# psoc4000t register map
Vendor: Cypress Semiconductor; Series: PSoC4000T; File version: 1.0
CPU: CM0PLUS r0p1, little endian, no MPU, no FPU, VTOR, 2 interrupt priority bits
Registers are 32-bit, read-write, reset 0x0 unless marked. A register's access mark holds for its fields unless they carry their own. Offsets are from the block's base; [hi:lo] are bit positions; lines under a group give offsets from that group; {n}, {i} and the like mark numbered series; 'fields as' and 'values as' point back to an identical list; <NAME> marks a mode.

## MSCLP0 (part 3 of 3) — Low Power MultiSense Converter
Base 0x40290000
0x2000 SNS group — Sensor Configuration Structure (clk_imo_msc domain)
  {0x0+4j} SENSOR_DATA[{j}] (j=0..1023) — Sensor Configuration Storage
    [31:0] DATA — Local IP storage to support per-sensor configuration and results for AS-MS/LP-AoS mode. The per sensor registers all have the prefix SNS_* in the SNS_STRUCTLP register tab. Firmware Rule: SENSOR_DATA represents design time parameter SRAM_SIZE (0,1,2,4) kB of storage that is usable for autonomous sensor configuration data and result data. It is accessed via 32-bit word indices. Firmware must program the following registers in a manner to allow for SENSOR_DATA to be used for both purposes (configuration and result). Sensor configuration: FRAME_CFG_START_ADDR is set by software to indicate to hardware where the first sensor scan configuration structure exists in SENSOR_DATA to start processing a frame (typically set to 0x0). The size of each configuration structure depends on what software sets for CFG_OFFSET (see description of this register for more details). Autonomous scanning will execute sequential structures (size defined by CFG_OFFSET) until it encounters a structure with SNS_CTL.LAST set. This defines the end of the frame. Sensor results: FRAME_RES_START_ADDR is set by software to define the base address (in 32-bit words) of the result FIFO (where the frame raw counts are stored). The depth of the FIFO is inferred by the setting for FRAME_RES_START_ADDR and the size of the memory integrated by the IP (SRAM_SIZE parameter). For example if SRAM_SIZE = 1kB, there are 256x 32-bit entries in the SRAM (0->255). If FRAME_RES_START_ADDR is set to 224, then the FIFO depth = 255-224+1 = 32. The result data is directly accessible by firmware via SENSOR_DATA (with an understanding of FRAME_RES_START_ADDR to know which index in SENSOR_DATA to access). The result FIFO can also be accessed as a FIFO via RESULT_FIFO_RD, which always points to the head of the FIFO (as tracked by hardware) and a read to this register pops the top result off this FIFO. See description of RESULT_FIFO_RD for details. Note that depending on the size of the SRAM macro integrated with the IP, and the amount of sensors being scanned (and amount of autonomous configuration required) - it is possible to have multiple sets of frame configuration and/or have the result FIFO sized to store multiple frames of data.
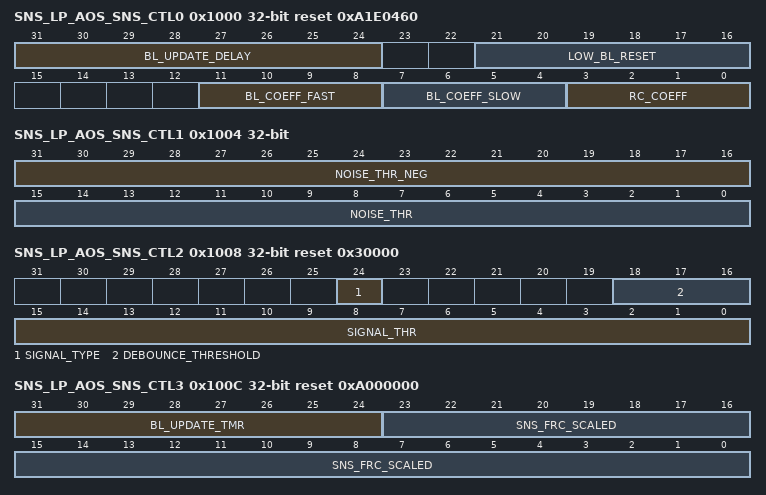
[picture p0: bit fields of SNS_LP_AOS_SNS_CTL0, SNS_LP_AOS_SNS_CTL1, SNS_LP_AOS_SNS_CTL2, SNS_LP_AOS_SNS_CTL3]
  0x1000 SNS_LP_AOS_SNS_CTL0 reset 0xA1E0460 — LP-AoS Sensor Control 0
    [31:24] BL_UPDATE_DELAY — Specifies the value from which BL_UPDATE_TMR is decremented from on consecutive scans where the baseline update IIR produces a zero. Used to enable a bucket filter at a programmable tuning rate.
    [21:16] LOW_BL_RESET — Specifies the value from which BL_RESET_TMR is decremented from on consecutive scans where diff as per SIGNAL_TYPE is below NOISE_THR and -diff is above NOISE_THR_NEG.
    [11:8] BL_COEFF_FAST — Baseline update IIR coefficient when baseline update state is fast. Firmware Rule: Must be > 0. Typical range [4,8].
      1=MIN (N/A)
    [7:4] BL_COEFF_SLOW — Baseline update IIR coefficient when baseline update state is slow. Firmware Rule: Must be > 0. Typical range [4,8].
      1=MIN (N/A)
    [3:0] RC_COEFF — Raw count filter coefficient. Firmware Rule: Legal range [0,8].
      8=MAX (N/A)
  0x1004 SNS_LP_AOS_SNS_CTL1 — LP-AoS Sensor Control 1
    [31:16] NOISE_THR_NEG — Sensor baseline negative noise threshold.
    [15:0] NOISE_THR — Sensor baseline noise threshold.
  0x1008 SNS_LP_AOS_SNS_CTL2 reset 0x30000 — LP-AoS Sensor Control 2
    [24] SIGNAL_TYPE — Setting that specifies whether the raw counts increase or decrease when the sensor is excited by an event (e.g. when a finger approaches a sensor - if self-cap sensing is used, the raw counts increase, but if mutual-cap sensing is used the raw counts decrease). '0': Positive - raw counts increase on event so for baselining diff = raw_count - baseline '1': Negative - raw counts decrease on event so for baselining diff = raw_count - baseline
      0=POSITIVE (N/A); 1=NEGATIVE (N/A)
    [18:16] DEBOUNCE_THRESHOLD — Global threshold for successive SIGNAL_THR exceeds to warrant a full system wakeup.
    [15:0] SIGNAL_THR — Per sensor threshold for |baseline - rawCount| to warrant a signal detect.
  0x100C SNS_LP_AOS_SNS_CTL3 reset 0xA000000 — LP-AoS Sensor Control 3
    [31:24] BL_UPDATE_TMR — Sensor baseline update timer. Decremented from BL_UPDATE_DELAY on consecutive scans where the baseline update IIR produces a zero. Used to enable a bucket filter.
    [23:0] SNS_FRC_SCALED — Sensor raw count filter IIR state (filtered raw count scaled).
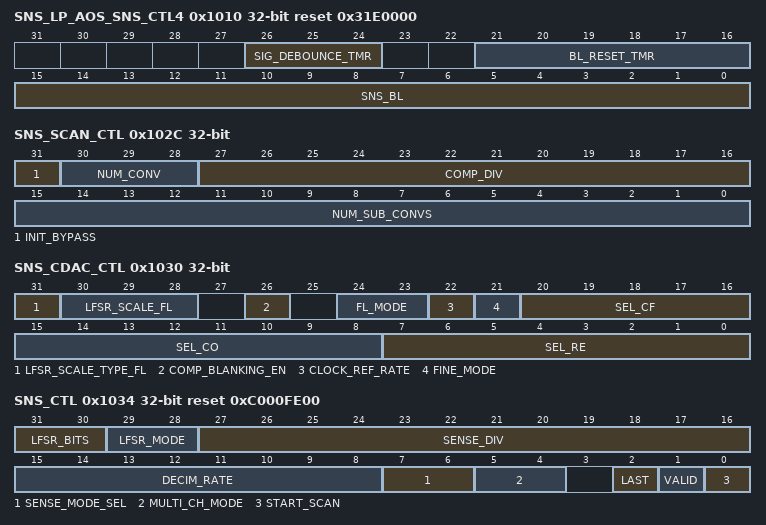
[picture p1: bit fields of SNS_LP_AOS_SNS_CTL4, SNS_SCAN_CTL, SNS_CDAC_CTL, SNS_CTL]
  0x1010 SNS_LP_AOS_SNS_CTL4 reset 0x31E0000 — LP-AoS Sensor Control 4
    [26:24] SIG_DEBOUNCE_TMR — Sensor signal detect debounce timer. Decremented from DEBOUNCE_THRESHOLD on consecutive scans with a signal detection.
    [21:16] BL_RESET_TMR — Sensor low baseline reset timer. Decremented from LOW_BL_RESET tuning parameter on consecutive scans where diff as per SIGNAL_TYPE is below NOISE_THR and -diff is above NOISE_THR_NEG.
    [15:0] SNS_BL — Sensor baseline value.
  0x1014 SNS_SW_SEL_CSW_HI_MASK2 — CapSense Sensor Switch Function Select High Mask 2
    [31:0] FUNC_MASK — {SNS_SW_SEL_CSW_HI_MASK2.FUNC_MASK[x], SNS_SW_SEL_CSW_HI_MASK1.FUNC_MASK[x], SNS_SW_SEL_CSW_HI_MASK0.FUNC_MASK[x]} used to select appropriate SW_SEL_CSW_FUNC[x] when CSW_FUNC_MODE[x] = 1.
  0x1018 SNS_SW_SEL_CSW_HI_MASK1 — CapSense Sensor Switch Function Select High Mask 1
    fields as SNS.SNS_SW_SEL_CSW_HI_MASK2
  0x101C SNS_SW_SEL_CSW_HI_MASK0 — CapSense Sensor Switch Function Select High Mask 0
    fields as SNS.SNS_SW_SEL_CSW_HI_MASK2
  0x1020 SNS_SW_SEL_CSW_LO_MASK2 — CapSense Sensor Switch Function Select Low Mask 2
    [31:0] FUNC_MASK — {SNS_SW_SEL_CSW_LO_MASK2.FUNC_MASK[x], SNS_SW_SEL_CSW_LO_MASK1.FUNC_MASK[x], SNS_SW_SEL_CSW_LO_MASK0.FUNC_MASK[x]} used to select appropriate SW_SEL_CSW_FUNC[x] when CSW_FUNC_MODE[x] = 1.
  0x1024 SNS_SW_SEL_CSW_LO_MASK1 — CapSense Sensor Switch Function Select Low Mask 1
    fields as SNS.SNS_SW_SEL_CSW_LO_MASK2
  0x1028 SNS_SW_SEL_CSW_LO_MASK0 — CapSense Sensor Switch Function Select Low Mask 0
    fields as SNS.SNS_SW_SEL_CSW_LO_MASK2
  0x102C SNS_SCAN_CTL — Sensor Scan Control
    [31] INIT_BYPASS — Coarse initialisation bypass control. Applies to CMOD_SEL selected Cmod.
      0=DISABLED (N/A); 1=ENABLED (N/A)
    [30:28] NUM_CONV — Number of conversions (minus 1) per scanned sample. This is required for chopping (chop polarity is updated per conversion).
      0=ONE (N/A); 1=TWO (N/A); 3=FOUR (N/A); 7=EIGHT (N/A)
    [27:16] COMP_DIV — The ratio (minus 1) of clk_comp::clk_mod. Notes for tuning: Fs = Fmod / Kref Fcomp = Kcomp * Fs MSCv3 MMIO provides: Kref = (SENSE_DIV+1) Fs = Fmod/(SENSE_DIV+1) Fcomp = Fmod / (COMP_DIV+1) Therefore: Kcomp = Fmod/[Fs*(COMP_DIV+1)] Kcomp = (SENSE_DIV+1)/(COMP_DIV+1) Hardware Overriding: Note that clk_comp runs at clk_ref (and associated duty cycle) during PRO_OFFSET, and COMP_DIV does not apply during this time. Firmware Rule: It is expected that Kcomp be programmed as an integer. Anything else is considered a mis-programming.
    [15:0] NUM_SUB_CONVS — Number of sub-conversions (minus 1) in a conversion.
  0x1030 SNS_CDAC_CTL — Sensor CAPDAC Control
    [31] LFSR_SCALE_TYPE_FL — Flatspot/Dither CAPDAC shift direction.
      0=RIGHT (N/A); 1=LEFT (N/A)
    [30:28] LFSR_SCALE_FL — Shift the magnitude portion of the Flatspot/Dither CAPDAC LFSR output code left or right by LSFR_SCALE_FL bits. Direction of shift controlled by LFSR_SCALE_TYPE_FL. Note since the magnitude is 7-bits, the maximum shift is 6-bits. The sign bit does not form part of the shift. Example: 6-bit polynomial (x^6 + x^4 + x^3 + x^2 + 1). lfsr_fl_out[7] = lfsr_fl[5]; // Sign bit always connected in MSB to HardIP. if(LFSR_SCALE_TYPE_FL == LEFT) lfsr_out[6:0] = {2'b00,lfsr[4:0]} << LFSR_SCALE_FL; // Scaled 7-bit magnitude. else lfsr_out[6:0] = {2'b00,lfsr[4:0]} >> LFSR_SCALE_FL; // Scaled 7-bit magnitude.
      6=MAX (N/A)
    [26] COMP_BLANKING_EN — Compensation blanking control. Type of blanking controlled by COMP_BLANKING_MODE. Effect of blanking defined as i) Gate to 0 (not freeze) clk_comp. ii) Open all SW_CO* switches. iii) Open all SW_CF* switches if being used in compensation mode (FINE_MODE = COMPENSATION). Hardware Overriding: General overriding as per general definition above. However the window in which these effects apply depend on the following. When enabled and in Direct Clock and Spread Spectrum mode (LFSR_MODE): 2-Phase: 50 percent Comp: PH0: Enable Comp for (SENSE_DIV+1)/4 (this will be 0.5 of Ph0 phase) PH1: Enable Comp for (SENSE_DIV+1)/4 (this will be 0.5 of Ph1 phase) 25 percent Comp: PH0: Enable Comp for (SENSE_DIV+1)/8 (this will be 0.25 of Ph0 phase) PH1: Enable Comp for (SENSE_DIV+1)/8 (this will be 0.25 of Ph1 phase) 4-Phase: 50 percent Comp: PH1: Enable Comp for (SENSE_DIV+1)/4 (this will be Full of Ph1 phase) PH3: Enable Comp for (SENSE_DIV+1)/4 (this will be Full of Ph3 phase) 25 percent Comp: PH1: Enable Comp for (SENSE_DIV+1)/8 (this will be 0.5 of Ph1 phase) PH3: Enable Comp for (SENSE_DIV+1)/8 (this will be 0.5 of Ph3 phase) Note that in Spread Spectrum mode, if the ph* where compensation is on shrinks from the nominal. So, if we have 50 percent compensation the ph can shrink to be shorter than (SENSE_DIV+1)/4. So for example if ph1 shrinks, this will mean that compensation stays on a bit into ph2. This is OK. When enabled and in PRS mode (LFSR_MODE): 2-Phase PRS: 50 percent Comp: PH0: Enable Comp for (SENSE_DIV+1) (this will be 0.5 of AVG Ph0 and All of MIN Ph0) PH1: Enable Comp for (SENSE_DIV+1) (this will be 0.5 of AVG Ph1 and All of MIN Ph1) 25 percent Comp: PH0: Enable Comp for (SENSE_DIV+1)/2 (this will be 0.25 of AVG Ph0 and 0.5 of Min Ph0) PH1: Enable Comp for (SENSE_DIV+1)/2 (this will be 0.25 of AVG Ph1 and 0.5 of Min Ph1) 4-Phase PRS: 50 percent Comp: PH1: Enable Comp for (SENSE_DIV+1)*2 (this will be All of AVG Ph1 and 2x of Min Ph1 or All of Min Ph1+Min Ph2) PH3: Enable Comp for (SENSE_DIV+1)*2 (this will be All of AVG Ph3 and 2x of Min Ph3 or All of Min Ph3+Min Ph0) 25 percent Comp: PH1: Enable Comp for (SENSE_DIV+1) (this will be 0.5 of AVG Ph1 and All of Min Ph1) PH3: Enable Comp for (SENSE_DIV+1) (this will be 0.5 of AVG Ph3 and All of Min Ph3)
      0=DISABLED (N/A); 1=ENABLED (N/A)
    [24:23] FL_MODE — Dither/Flatspot LFSR enable control. Hardware Overriding: '0': Dither/Flatspot LFSR is disabled. LFSR_SCALE_FL, LFSR_SCALE_TYPE_FL and ACTIVATION_MODE and MSB manipulation logic have no effect. The hard IP is presented with the code 0x00 and SEL_FL programming is ignored. All SW_SEL_CDAC_FL switches are autonomously kept open during PRO_DUMMY, PRO_WAIT, SUB_CONV, EPILOGUE and POST_EPI states. '1': The Dither/Flatspot LFSR is enabled. There is no overriding of SW_SEL_CDAC_FL even if LFSR is at a zero code. '2': Dither/Flatspot LFSR is used as an offset (SEL_FL specified). LFSR_SCALE_FL, LFSR_SCALE_TYPE_FL and ACTIVATION_MODE and MSB manipulation logic have no effect. The hard IP is presented with the code programmed into SEL_FL. If SEL_FL is 0x00 (unlikely programming in this mode), then all SW_SEL_CDAC_FL switches are autonomously kept open for the duration of the PRO_DUMMY, PRO_WAIT, SUB_CONV, EPILOGUE and POST_EPI states.
      0=DISABLED (N/A); 1=DITHER (N/A); 2=OFFSET (N/A)
    [22] CLOCK_REF_RATE — Used to select clk_mod or clk_mod/2 to as clk_ref. This clock is gated depending on the synchronised comparator to generate the gated feedback clock (clk_reffb) to the Reference CAPDAC. '0': Use clk_mod. '1': Use clk_mod/2.
      0=CLK_MOD (N/A); 1=HALF_CLK_MOD (N/A)
    [21] FINE_MODE — Operational mode for Fine CAPDAC
      0=REFERENCE (N/A); 1=COMPENSATION (N/A)
    [20:16] SEL_CF — Select value for Fine CAPDAC size. Hardware Overriding: If SEL_CF = 0 Hardware provides autonomous overriding of all SW_SEL_CDAC_CF to be OPEN for the duration of the PRO_DUMMY, PRO_WAIT, SUB_CONV, EPILOGUE and POST_EPI states. This is true for both FINE_MODE = REFERENCE/COMPENSATION.
    [15:8] SEL_CO — Select value for Compensation CAPDAC size. Hardware Overriding: Note if SEL_CO = 0 and FINE_MODE != COMPENSATION, then clk_comp is gated during PRO_DUMMY, SUB_CONV and EPILOGUE. Additionally: If SEL_CO = 0 Hardware provides autonomous overriding of all SW_SEL_CDAC_CO to be OPEN for the duration of the PRO_DUMMY, PRO_WAIT, SUB_CONV, EPILOGUE and POST_EPI states.
    [7:0] SEL_RE — Select value for Reference CAPDAC size. Hardware Overriding: If SEL_RE = 0 Hardware provides autonomous overriding of all SW_SEL_CDAC_RE to be OPEN for the duration of the PRO_DUMMY, PRO_WAIT, SUB_CONV, EPILOGUE and POST_EPI states.
  0x1034 SNS_CTL reset 0xC000FE00 — Sense Control and Command Register
    [31:30] LFSR_BITS — Selects the number of LSB bits to use from the LSFR to provide the clock dithering variation on the base period (spread spectrum mode). Caveat make sure that SENSE_DIV > the maximum absolute range (e.g. for 4B SENSE_DIV > 8), otherwise results are undefined.
      0=2B (Use 2 bits: range = [-2,1]); 1=3B (Use 3 bits: range = [-4,3]); 2=4B (Use 4 bits: range = [-8,7]); 3=5B (Use 5 bits: range = [-16,15] (default))
    [29:28] LFSR_MODE — Mode for generating the sense clock. '0': Direct Clocking. '1': Spread Spectrum. '2': PRS.
      0=DIRECT_CLOCK (N/A); 1=SPREAD_SPECTRUM (N/A); 2=PRS (N/A)
    [27:16] SENSE_DIV — The length (minus 1) of the sense modulation 'clock' period in clk_mod cycles (frequency = Fs). SENSE_DIV + 1 = sense_ratio = Kref. Note this is the base divider, clock dithering may change the actual period length. Firmware Rule: Firmware is responsible for programming a value in this register to ensure correct operation. When LFSR_MODE = DIRECT_CLOCK, in 2-phase mode sense_ratio needs to be >=4 to allow for digital non-overlap. In 4-phase mode, sense_ratio needs to be >=8. If spread spectrum is enabled (LFSR_MODE = SPREAD_SPECTRUM), SENSE_DIV must be programmed large enough to ensure that negative dithering does not cause sense_ratio to become too small. It is possible for SENSE_DIV to be as low as zero though when LFSR_MODE = PRS (if digital non-overlap is disabled). This is because in PRS mode, SENSE_DIV defines the rate at which the LFSR is clocked and the MSB of the LFSR is used to create the phase signals.
    [15:8] DECIM_RATE — Sets the decimation rate for the sinc^2 filter (CIC2). Typically referred to as N. Note N = DECIM_RATE + 1. Only applies when FILTER_CTL.FILTER_MODE = CIC2, and irrelevant for CIC1 mode (no effect in this mode). Maximum value out of CIC2 is N^2 (unsigned input) and +/- N^2 (signed input). Since CIC2 uses a 16-bit pipeline, the maximum range is [0,2^16-1] (unsigned) and [-2^15,2^15-1] (signed). This implies a limitation on maximum usable DECIM_RATE depending on BIT_FORMAT signed/unsigned. BIT_FORMAT = UNSIGNED -> DECIM_RATE(max) = 254 (N = 255). BIT_FORMAT = SIGNED -> DECIM_RATE(max) = 180 (N = 181). The scan time for M-bit scan is 2^M clk_mod cycles. This value is determined by (SENSE_DIV+1)*(NUM_SUB_CONVS+1). Note that the CIC2 filter does not operate in the EPILOGUE state, so NUM_EPI_CYCLES does not feed into the above equation.
    [7:6] SENSE_MODE_SEL — Sense mode register structure selection. This field allows quick change between registers that influence sense mode. This register selects which structure is currently 'live' and used by the IP. These registers are captured in MODE_STRUCT. The usable values in this register is determined by design time parameter SENSE_MODE_NR.
      {v}=SENSE_MODE_{v} (Use MODE_STRUCT[{v}].) (v=0..3)
    [5:4] MULTI_CH_MODE — Multi channel mode configuration. Determines whether consensus mechanism is engaged to ensure channels scan in lockstep. '0': Single channel. '1': Wait for internal sync (on-chip). '2': Wait for external sync (off-chip).
      0=OFF (N/A); 1=INTERNAL (N/A); 2=EXTERNAL (N/A)
    [2] LAST — Indicator that current sensor configuration is the last sensor in the frame.
    [1] VALID — Indicator of sensor configuration validity.
    [0] START_SCAN — Start the MSCv3 sequencer scan process. The sequencer will clear this bit when it is done. Depending on the mode the sequencer is done when all NUM_SAMPLES for this scan have been accumulated, or if the sequencer is reset.
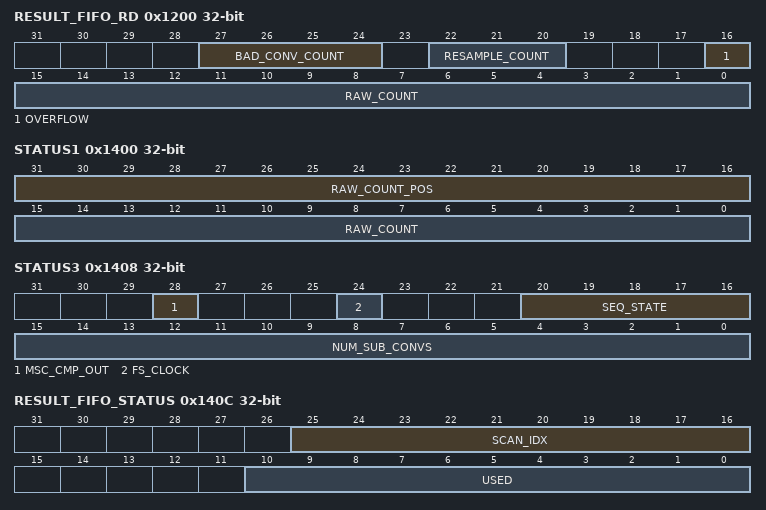
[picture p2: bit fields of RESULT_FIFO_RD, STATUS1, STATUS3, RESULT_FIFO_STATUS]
  0x1200 RESULT_FIFO_RD ro — Result FIFO Pointer
    [27:24] BAD_CONV_COUNT — Counter to indicate whether conversion of a sample is bad at the end of each chop phase. This is true if the comparator has not tripped by the end of EPILOGUE in a chop phase. BAD_CONV_COUNT can have a maximum value of 8 (based on largest legal NUM_CONV). If RESAMPLE_COUNT > 0 and BAD_CONV_COUNT = 0, this indicates that RESAMPLE_COUNT bad samples were encountered before this good sample was obtained. If RESAMPLE_COUNT > 0 and BAD_CONV_COUNT > 0, this indicates that all NUM_AUTO_RESAMPLE attempts have been executed and the final attempt had BAD_CONV_COUNT bad conversions. In this situation RESAMPLE_COUNT should equal NUM_AUTO_RESAMPLE.
    [22:20] RESAMPLE_COUNT — Counter indicating number of attempted re-samples (via NUM_AUTO_RESAMPLE) for this raw count. If RESAMPLE_COUNT = 0 and NUM_AUTO_RESAMPLE > 0, this raw count was obtained from the first sample attempt.
    [16] OVERFLOW — RAW_COUNT overflow.
    [15:0] RAW_COUNT — FILTER_MODE = CIC1: Accumulated raw count for a sample (post raw count filtering if RCF_EN = 1 and CE_CTL.ENABLED = 1). FILTER_MODE = CIC2: Average value of all valid sub-samples over all conversions in a sample (post raw count filtering if RCF_EN = 1 and CE_CTL.ENABLED = 1). Note that the hardware averaging capabilities are limited. See INTR.CIC2_ERROR - if this interrupt asserts it *may* be possible to firmware back calculate the correct average. See SCAN_CTL1.RAW_COUNT_MODE for overflow behaviour of RAW_COUNT. Firmware Rule: Accessing this register (RESULT_FIFO_RD) pops the top result off the FIFO (unless a DAP access which peeks the FIFO). The definition of this FIFO and the dimensioning is described in the SENSOR_DATA register description. Firmware may query the state of this FIFO at any time via the RESULT_FIFO_STATUS* registers.
  0x1400 STATUS1 ro — General Status Register 1
    [31:16] RAW_COUNT_POS — Useful for determining component counts for positive and negative charge by subtracting from RAW_COUNT. When PHASE_MODE_SEL = FOUR_PHASE RAW_COUNT_POS: Counts during ph1/ph2 of SUB_CONV. When PHASE_MODE_SEL = TWO_PHASE RAW_COUNT_POS: Counts during ph0 of SUB_CONV. This counter increments whenever the Cref CAPDAC is balancing during the corresponding phases above. Note that digital non-overlap is ignored for the purposes of this count since balancing occurs irrespective of these settings. Hence the 'raw' phases (pre application of any digital non-overlap) are considered as the measurement window for this counter. Applicable for CIC1 and CIC2 mode. In CIC2 mode the count is determined by the value of the input to the first integrator stage (equivalent to CIC1 behaviour).
    [15:0] RAW_COUNT — Live current raw counter (pre any Channel Engine raw count filtering). For debug/test purposes. In normal operation, Firmware/DMA will typically read results from RESULT_FIFO_RD. The result FIFO value has accounted for Channel Engine raw count filtering. Note that in CIC2 mode, this value gets updated at the decimation rate. When the SUB_SAMPLE interrupt is asserted, firmware could read this value before the next SUB_SAMPLE interrupt fires to debug sub-samples if desired.
  0x1404 STATUS2 ro — General Status Register 2
    [15:0] DEBUG_CONV_COUNT — Debug raw count for a particular conversion. Enabled only during a specified conversion of a sample (a specific chop phase). Only applicable for CIC1 mode. In CIC2 mode this counter remains zero.
  0x1408 STATUS3 ro — General Status Register 3
    [28] MSC_CMP_OUT — Output of main sensing comparator (synchronized). For debug/test purposes.
    [24] FS_CLOCK — Sense clock Fs control waveform. For debug/test purposes.
    [20:16] SEQ_STATE — MSC Sequencer FSM state.
      0=IDLE (N/A); 1=WAIT_DMA_WRITE (N/A); 2=LOAD_CONFIG (N/A); 3=WAIT_SCAN_START (N/A); 4=ASSERT_RDY (N/A); 5=WAIT_CONSENSUS (N/A); 6=INIT_CMOD (N/A); 7=INIT_SHORT (N/A); 8=PRO_OFFSET (N/A); 9=PRO_DUMMY (N/A); 10=PRO_WAIT (N/A); 11=SUB_CONV (N/A); 12=EPILOGUE (N/A); 13=WAIT_DMA_READ_NEW_SAMPLE (N/A); 14=WAIT_DMA_READ_EOF (N/A); 15=POST_SCAN (N/A); 16=POST_EPI (N/A)
    [15:0] NUM_SUB_CONVS — Number of sub-conversions remaining while in PRO_DUMMY and SUB_CONV.
  0x140C RESULT_FIFO_STATUS ro
    [25:16] SCAN_IDX — Scan index counter within a frame. This index increments at the end of every scan co-incident with INTR.SCAN for SNS_CTL.VALID scan indices (but also increments for invalid scan indices when SNS_CTL.VALID = 0). This index is set to 0 at the end of the first scan of a frame and will increment up to the last scan in the frame as defined by SNS_CTL.LAST.
    [10:0] USED — Number of used/occupied entries in the result FIFO. When '0', the FIFO is empty.
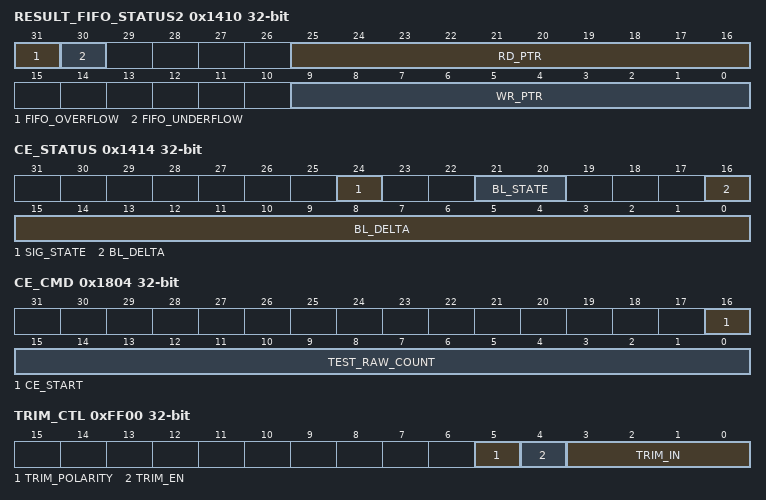
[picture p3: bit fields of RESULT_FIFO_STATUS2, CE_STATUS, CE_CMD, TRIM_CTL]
  0x1410 RESULT_FIFO_STATUS2 ro
    [31] FIFO_OVERFLOW — Set if hardware attempts to write a RAW_COUNT (and associated metrics) to an already full result FIFO.
    [30] FIFO_UNDERFLOW — Hardware sets this field to '1', when reading from an empty FIFO (RESULT_FIFO_STATUS.USED is '0').
    [25:16] RD_PTR — Result FIFO read pointer: FIFO location from which data is read via AHB. Note: This functionality is intended for debugging purposes.
    [9:0] WR_PTR — Result FIFO write pointer: FIFO location at which a new data is written by the hardware. Note: This functionality is intended for debugging purposes.
  0x1414 CE_STATUS ro — Channel Engine Status
    [24] SIG_STATE — Current sensor signal state.
    [21:20] BL_STATE — Channel Engine baseline update state.
      0=INIT (Initialise baseline to raw count.); 1=UPDATE_SLOW (Slow baseline update when raw count minus baseline exceeds sensor noise threshold.); 2=UPDATE_FAST (Fast baseline update when baseline minus raw count exceeds sensor negative noise threshold.)
    [16:0] BL_DELTA — Current value of Channel Engine baseline update delta (int17 format).
  0x1418 BRIDGE_STATUS ro reset 0x1 — AHB2AHB Bridge Status
    [0] READY — Status bit to indicate that the logic behind the AHB2AHB bridge has fully completed the side effect of all buffered write transactions. The bridge itself enforces buffered writes regardless of AHB hprot[3:0]. Firmware Rule: A read of this register is a mechanism for firmware to ensure that all previous write accesses to SNS_STRUCTLP have completed from an AHB point of view but also completed from a hardware point of view (target write location in hardware is written to). Reading this register is not necessary for FRAME_CMD.START_FRAME initiated frames (since this register exists on SNS_STRUCTLP) but is required prior to WAKEUP_CMD.START_FRAME_AOS (or any form of external frame start). After writing to the SNS_STRUCTLP bank, the firmware should inspect this bit and detect READY = 1 before issuing an external frame start or WAKEUP_CMD.START_FRAME_AOS (to avoid a potential race condition where SNS_STRUCTLP MMIO are not set before the frame starts).
  0x1800 FRAME_CMD — Frame Command Register
    [0] START_FRAME — Start the MSCv3 sequencer frame process. Note that a rising edge on this bit also creates a 4x cycle clk_msc pulse on the msc_ext_frm_start_out signal (when EXT_FRAME_START_MODE = DISABLED). The corresponding msc_ext_frm_start_out_en is controlled by CTL.ENABLED. Sequencer FSM clears this bit on egress from IDLE. If START_FRAME is set by firmware when FSM is not in IDLE, the hardware must hold the bit set to allow for 'pending' frame behaviour. Firmware Rule: Note if FRAME_CMD is used in a multi-channel scenario care must be taken by firmware not to excessively delay FRAME_CMD to each individual channel. If not, a window exists where the first channel that sees FRAME_CMD can reach the WAIT_CONSENSUS state and mistakenly believe all channels are ready for lockstep scanning when the reality is the other channels are still in IDLE and indicating ready because they haven't been initiated yet.
  0x1804 CE_CMD — Channel Engine Command
    [16] CE_START — Initiates Channel Engine processing if CE_TEST_MODE = 1.
    [15:0] TEST_RAW_COUNT — Firmware settable raw count for Channel Engine when CE_TEST_MODE = 1.
  0x1808 FIFO_CMD — FIFO Command
    [0] FIFO_RESET — Initiate a reset of the result FIFO. A write to this register causes the pointers and associated logic visible via RESULT_FIFO_STATUS and RESULT_FIFO_STATUS2 to be reset (FIFO is empty after this action). Firmware Rule: Firmware should not write to this register mid scan as no hardware protection is in place to avoid resetting the FIFO when it could be used by hardware. Firmware should only write to this register when the IP is idle.
  0x1C00 CE_INIT_CTL — Channel Engine Initialisation Control
    [0] SENSOR_INIT — Set by firmware when hardware initialisation of the raw count filter and baselines is required for the first frame after FRAME_START_AOS, FRAME_START or an external frame start detected. Hardware clears this bit down at the end of this frame. Firmware Rule: Note if SENSOR_INIT = FW_INIT, it is the responsibility of firmware to program all of SNS_LP_AOS_SNS_CTLx registers appropriately prior to executing a frame.
      0=FW_INIT (N/A); 1=HW_INIT (N/A)
0xFF00 TRIM_CTL — Trim Control
  [5] TRIM_POLARITY — Controls polarity of comparator offset trim.
  [4] TRIM_EN — Enables comparator offset trim.
    0=DISABLED (N/A); 1=ENABLED (N/A)
  [3:0] TRIM_IN — Controls magnitude of comparator offset trim.
0xFF04 CLK_IMO_TRIM1 reset 0x80 — Local IMO Trim Register 1
  [7:0] OFFSET — Frequency trim bits. These bits are determined at manufacturing time for each FREQ setting (CLK_IMO_TRIM2) and stored in SFLASH. This field is mapped to the most significant bits of the IMO trim imo_clk_trim[10:3]. The step size of 1 LSB on this field is approximately 120 kHz.
0xFF08 CLK_IMO_TRIM2 — Local IMO Trim Register 2
  [2:0] FSOFFSET — Frequency trim bits. These bits are not trimmed during manufacturing and kept at 0 under normal operation. This field is mapped to the least significant bits of the IMO trim imo_clk_trim[2:0]. The step size of 1 LSB on this field is approximately 15 kHz.
0xFF0C CLK_IMO_TRIM3 reset 0x2 — Local IMO Trim Register 3
  [1:0] TCTRIM — IMO temperature compesation trim. These bits are determined at manufacturing time to adjust for temperature dependence. This bits are dependent on frequency and need to be changed using the Cypress provided frequency change algorithm.
0xFF10 PWR_BG_TRIM1 reset 0x10 — Bandgap Trim Register 1
  [5:0] REF_VTRIM — Trims the bandgap reference voltage output. Used to trim the VBG to the voltage where its temperature curvature is minimal. Bit [5] is unused within the bandgap block.
0xFF14 PWR_BG_TRIM2 reset 0x1C — Bandgap Trim Register 2
  [5:0] REF_ITRIM — Trims the bandgap reference current output. Used to trim the IBG to the voltage where its temperature curvature is minimal.
0xFF18 PWR_BG_TRIM3 — Bandgap Trim Register 3
  [3:0] REF_TCTRIM — Active-Reference temperature compensation trim (repurposed from spare bits). Bits [3:2] - trim the Active-Reference IREF temperature coefficient (TC). 00: TC = 0 (unchanged) 01: TC = +80ppm/C 10: TC = -80ppm/C 11: TC = -150ppm/C Bits [1:0] - trim the Active-Reference VREF temperature coefficient (TC). 00: TC = 0 (unchanged) 01: TC = -50ppm/C 10: TC = -80ppm/C 11: TC = +150ppm/C
